VERSION "gbt27930-test-1.0"

NS_ :

BS_:

BU_: SECC EVCC

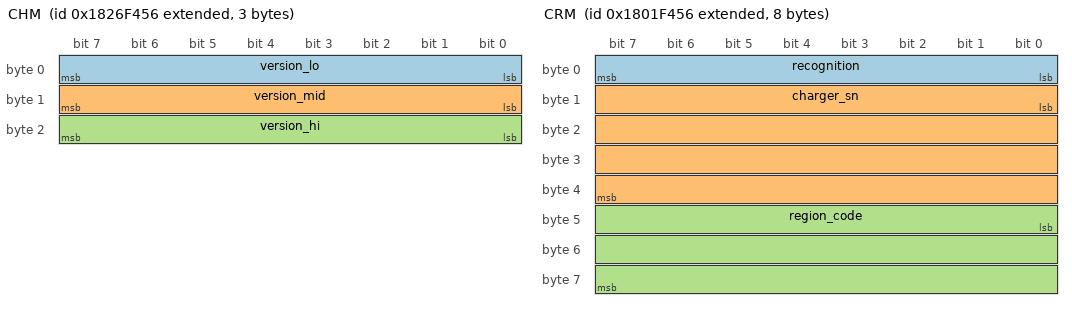
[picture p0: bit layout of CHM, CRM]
BO_ 2552689750 CHM: 3 SECC
 SG_ version_lo : 0|8@1+ (1,0) [0|255] "" SECC
 SG_ version_mid : 8|8@1+ (1,0) [0|255] "" SECC
 SG_ version_hi : 16|8@1+ (1,0) [0|255] "" SECC

BO_ 2552714996 BHM: 2 EVCC
 SG_ max_battery_voltage_v : 0|16@1+ (0.1,0) [0|65535] "V" EVCC

BO_ 2550264918 CRM: 8 SECC
 SG_ recognition : 0|8@1+ (1,0) [0|255] "" SECC
 SG_ charger_sn : 8|32@1+ (1,0) [0|4294967295] "" SECC
 SG_ region_code : 40|24@1+ (1,0) [0|16777215] "" SECC

BO_ 2550552308 BCP: 13 EVCC
 SG_ max_cell_voltage_v : 0|16@1+ (0.01,0) [0|65535] "V" EVCC
 SG_ max_charge_current_a : 16|16@1+ (0.1,-400) [0|65535] "A" EVCC
 SG_ max_energy_kwh : 32|16@1+ (0.1,0) [0|65535] "kWh" EVCC
 SG_ max_total_voltage_v : 48|16@1+ (0.1,0) [0|65535] "V" EVCC
 SG_ max_temperature_c : 64|8@1+ (1,-50) [0|255] "C" EVCC
 SG_ soc : 72|16@1+ (0.1,0) [0|65535] "%" EVCC
 SG_ current_battery_voltage_v : 88|16@1+ (0.1,0) [0|65535] "V" EVCC

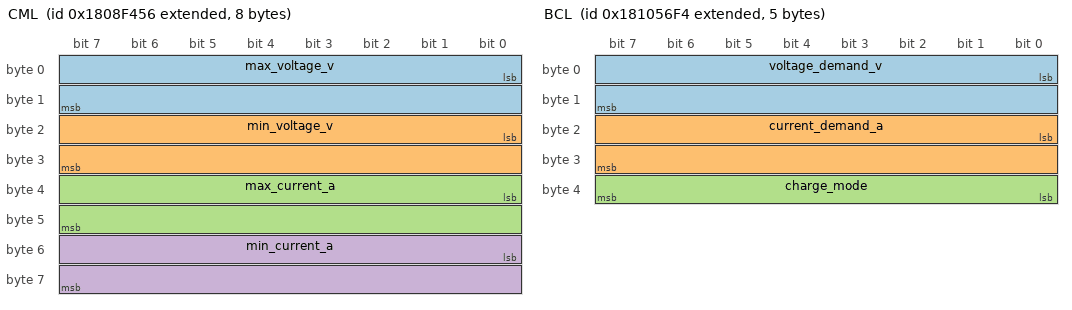
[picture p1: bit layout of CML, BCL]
BO_ 2550723670 CML: 8 SECC
 SG_ max_voltage_v : 0|16@1+ (0.1,0) [0|65535] "V" SECC
 SG_ min_voltage_v : 16|16@1+ (0.1,0) [0|65535] "V" SECC
 SG_ max_current_a : 32|16@1+ (0.1,-400) [0|65535] "A" SECC
 SG_ min_current_a : 48|16@1+ (0.1,-400) [0|65535] "A" SECC

BO_ 2550748916 BRO: 1 EVCC
 SG_ ready : 0|8@1+ (1,0) [0|255] "" EVCC

BO_ 2550854742 CRO: 1 SECC
 SG_ ready : 0|8@1+ (1,0) [0|255] "" SECC

BO_ 2551207668 BCL: 5 EVCC
 SG_ voltage_demand_v : 0|16@1+ (0.1,0) [0|65535] "V" EVCC
 SG_ current_demand_a : 16|16@1+ (0.1,-400) [0|65535] "A" EVCC
 SG_ charge_mode : 32|8@1+ (1,0) [0|255] "" EVCC

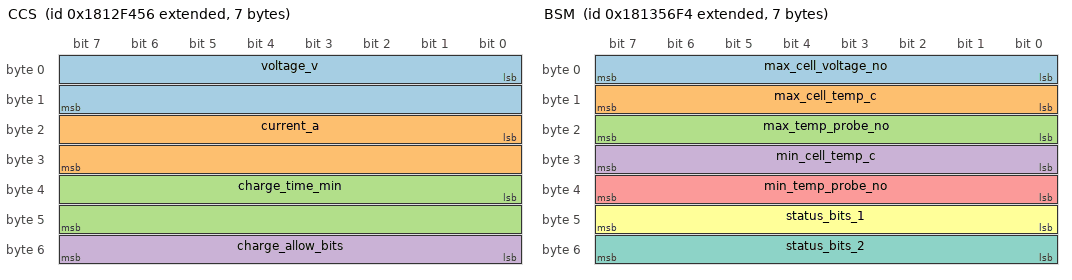
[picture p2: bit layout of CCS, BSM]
BO_ 2551379030 CCS: 7 SECC
 SG_ voltage_v : 0|16@1+ (0.1,0) [0|65535] "V" SECC
 SG_ current_a : 16|16@1+ (0.1,-400) [0|65535] "A" SECC
 SG_ charge_time_min : 32|16@1+ (1,0) [0|65535] "min" SECC
 SG_ charge_allow_bits : 48|8@1+ (1,0) [0|255] "" SECC

BO_ 2551404276 BSM: 7 EVCC
 SG_ max_cell_voltage_no : 0|8@1+ (1,0) [0|255] "" EVCC
 SG_ max_cell_temp_c : 8|8@1+ (1,-50) [0|255] "C" EVCC
 SG_ max_temp_probe_no : 16|8@1+ (1,0) [0|255] "" EVCC
 SG_ min_cell_temp_c : 24|8@1+ (1,-50) [0|255] "C" EVCC
 SG_ min_temp_probe_no : 32|8@1+ (1,0) [0|255] "" EVCC
 SG_ status_bits_1 : 40|8@1+ (1,0) [0|255] "" EVCC
 SG_ status_bits_2 : 48|8@1+ (1,0) [0|255] "" EVCC

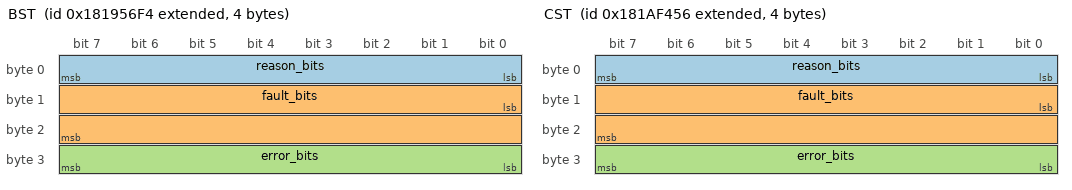
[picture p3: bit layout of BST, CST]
BO_ 2551797492 BST: 4 EVCC
 SG_ reason_bits : 0|8@1+ (1,0) [0|255] "" EVCC
 SG_ fault_bits : 8|16@1+ (1,0) [0|65535] "" EVCC
 SG_ error_bits : 24|8@1+ (1,0) [0|255] "" EVCC

BO_ 2551903318 CST: 4 SECC
 SG_ reason_bits : 0|8@1+ (1,0) [0|255] "" SECC
 SG_ fault_bits : 8|16@1+ (1,0) [0|65535] "" SECC
 SG_ error_bits : 24|8@1+ (1,0) [0|255] "" SECC

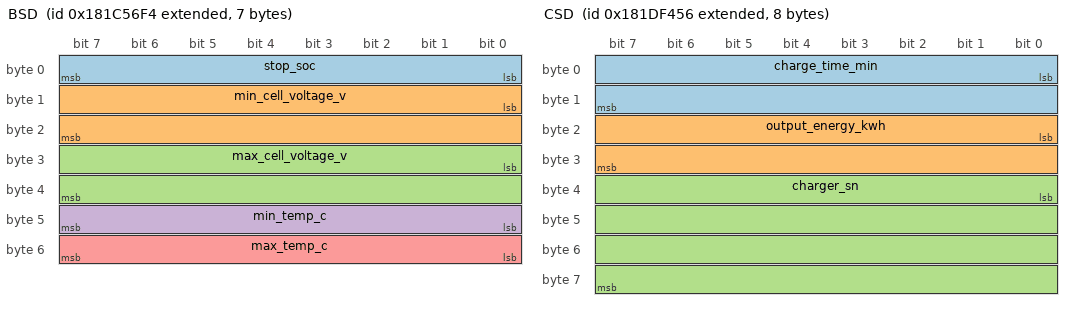
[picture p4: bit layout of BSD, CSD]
BO_ 2551994100 BSD: 7 EVCC
 SG_ stop_soc : 0|8@1+ (1,0) [0|255] "%" EVCC
 SG_ min_cell_voltage_v : 8|16@1+ (0.01,0) [0|65535] "V" EVCC
 SG_ max_cell_voltage_v : 24|16@1+ (0.01,0) [0|65535] "V" EVCC
 SG_ min_temp_c : 40|8@1+ (1,-50) [0|255] "C" EVCC
 SG_ max_temp_c : 48|8@1+ (1,-50) [0|255] "C" EVCC

BO_ 2552099926 CSD: 8 SECC
 SG_ charge_time_min : 0|16@1+ (1,0) [0|65535] "min" SECC
 SG_ output_energy_kwh : 16|16@1+ (0.1,0) [0|65535] "kWh" SECC
 SG_ charger_sn : 32|32@1+ (1,0) [0|4294967295] "" SECC

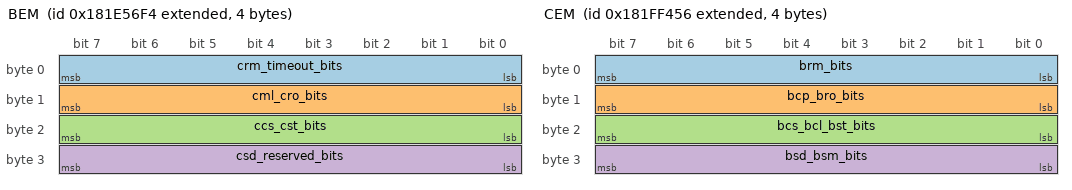
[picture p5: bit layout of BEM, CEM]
BO_ 2552125172 BEM: 4 EVCC
 SG_ crm_timeout_bits : 0|8@1+ (1,0) [0|255] "" EVCC
 SG_ cml_cro_bits : 8|8@1+ (1,0) [0|255] "" EVCC
 SG_ ccs_cst_bits : 16|8@1+ (1,0) [0|255] "" EVCC
 SG_ csd_reserved_bits : 24|8@1+ (1,0) [0|255] "" EVCC

BO_ 2552230998 CEM: 4 SECC
 SG_ brm_bits : 0|8@1+ (1,0) [0|255] "" SECC
 SG_ bcp_bro_bits : 8|8@1+ (1,0) [0|255] "" SECC
 SG_ bcs_bcl_bst_bits : 16|8@1+ (1,0) [0|255] "" SECC
 SG_ bsd_bsm_bits : 24|8@1+ (1,0) [0|255] "" SECC

BO_ 2550290164 BRM: 49 EVCC
 SG_ bms_protocol_ver : 0|8@1+ (1,0) [0|255] "" EVCC
 SG_ battery_type : 8|8@1+ (1,0) [0|255] "" EVCC
 SG_ rated_capacity_ah : 16|32@1+ (0.1,0) [0|4294967295] "Ah" EVCC
 SG_ rated_voltage_v : 48|16@1+ (0.1,0) [0|65535] "V" EVCC
 SG_ rated_energy_kwh : 64|32@1+ (0.1,0) [0|4294967295] "kWh" EVCC
 SG_ charge_count : 184|24@1+ (1,0) [0|16777215] "" EVCC

BO_ 2551273204 BCS: 9 EVCC
 SG_ avg_voltage_v : 0|16@1+ (0.1,0) [0|65535] "V" EVCC
 SG_ max_cell_voltage_v : 16|12@1+ (0.001,0) [0|4095] "V" EVCC
 SG_ max_cell_voltage_no : 28|4@1+ (1,0) [0|15] "" EVCC
 SG_ current_a : 32|16@1+ (0.1,-400) [0|65535] "A" EVCC
 SG_ soc : 48|16@1+ (0.1,0) [0|65535] "%" EVCC

BO_ 2565603414 TP_CM_SECC: 7 SECC
 SG_ control : 0|8@1+ (1,0) [0|255] "" SECC
 SG_ total_len : 8|16@1+ (1,0) [0|65535] "B" SECC
 SG_ total_pkts : 24|8@1+ (1,0) [0|255] "" SECC
 SG_ pgn : 40|24@1+ (1,0) [0|16777215] "" SECC
BO_ 2565537878 TP_DT_SECC: 8 SECC
 SG_ seq : 0|8@1+ (1,0) [0|255] "" SECC

BO_ 2565603572 TP_CM_EVCC: 7 EVCC
 SG_ control : 0|8@1+ (1,0) [0|255] "" EVCC
 SG_ total_len : 8|16@1+ (1,0) [0|65535] "B" EVCC
 SG_ total_pkts : 24|8@1+ (1,0) [0|255] "" EVCC
 SG_ pgn : 40|24@1+ (1,0) [0|16777215] "" EVCC
BO_ 2565538036 TP_DT_EVCC: 8 EVCC
 SG_ seq : 0|8@1+ (1,0) [0|255] "" EVCC

VAL_ 0 charge_mode 1 "恒压CV" 2 "恒流CC";
CM_ BO_ CHM "充电机握手报文 (GB/T 27930-2015 §11.1.1)";
CM_ BO_ BCL "BMS 充电需求 (§11.3.1, 周期 50ms)";
CM_ BO_ BSM "动力蓄电池状态信息 (§11.3.4, 周期 250ms)";
